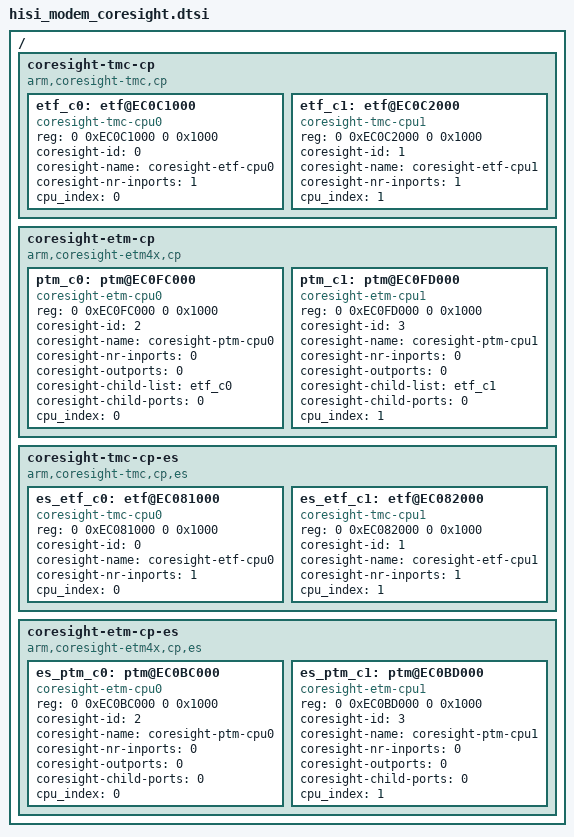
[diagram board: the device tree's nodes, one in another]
/*
 * Hisilicon Ltd Balong SOC
 */

/include/ "skeleton.dtsi"

/{
	coresight-tmc-cp {
		compatible = "arm,coresight-tmc,cp";
		ranges;
		/*tmc cpu 0*/
		etf_c0: etf@EC0C1000 {
			compatible = "coresight-tmc-cpu0";
			reg = <0 0xEC0C1000 0 0x1000>;
			
			coresight-id = <0>;
			coresight-name = "coresight-etf-cpu0";
			coresight-nr-inports = <1>;
			cpu_index = <0>;
		};
		/*tmc cpu 1*/
		etf_c1: etf@EC0C2000 {
			compatible = "coresight-tmc-cpu1";
			reg = <0 0xEC0C2000 0 0x1000>;
			
			coresight-id = <1>;
			coresight-name = "coresight-etf-cpu1";
			coresight-nr-inports = <1>;
			cpu_index = <1>;
		};		
	};
	coresight-etm-cp {
		compatible = "arm,coresight-etm4x,cp";
		ranges;
		/*etm cpu0*/
		ptm_c0: ptm@EC0FC000 {
			compatible = "coresight-etm-cpu0";
			reg = <0 0xEC0FC000 0 0x1000>;
			
			coresight-id = <2>;
			coresight-name = "coresight-ptm-cpu0";
			coresight-nr-inports = <0>;
			coresight-outports = <0>;
			coresight-child-list = <&etf_c0>;
			coresight-child-ports = <0>;
			cpu_index = <0>;
		};
		/*etm cpu1*/
		ptm_c1: ptm@EC0FD000 {
			compatible = "coresight-etm-cpu1";
			reg = <0 0xEC0FD000 0 0x1000>;
			
			coresight-id = <3>;
			coresight-name = "coresight-ptm-cpu1";
			coresight-nr-inports = <0>;
			coresight-outports = <0>;
			coresight-child-list = <&etf_c1>;
			coresight-child-ports = <0>;
			cpu_index = <1>;
		};		
	};
	coresight-tmc-cp-es {
		compatible = "arm,coresight-tmc,cp,es";
		ranges;
		/*tmc cpu 0*/
		es_etf_c0: etf@EC081000 {
			compatible = "coresight-tmc-cpu0";
			reg = <0 0xEC081000 0 0x1000>;
			
			coresight-id = <0>;
			coresight-name = "coresight-etf-cpu0";
			coresight-nr-inports = <1>;
			cpu_index = <0>;
		};
		/*tmc cpu 1*/
		es_etf_c1: etf@EC082000 {
			compatible = "coresight-tmc-cpu1";
			reg = <0 0xEC082000 0 0x1000>;
			
			coresight-id = <1>;
			coresight-name = "coresight-etf-cpu1";
			coresight-nr-inports = <1>;
			cpu_index = <1>;
		};		
	};
	coresight-etm-cp-es {
		compatible = "arm,coresight-etm4x,cp,es";
		ranges;
		/*etm cpu0*/
		es_ptm_c0: ptm@EC0BC000 {
			compatible = "coresight-etm-cpu0";
			reg = <0 0xEC0BC000 0 0x1000>;
			
			coresight-id = <2>;
			coresight-name = "coresight-ptm-cpu0";
			coresight-nr-inports = <0>;
			coresight-outports = <0>;
			coresight-child-ports = <0>;
			cpu_index = <0>;
		};
		/*etm cpu1*/
		es_ptm_c1: ptm@EC0BD000 {
			compatible = "coresight-etm-cpu1";
			reg = <0 0xEC0BD000 0 0x1000>;
			
			coresight-id = <3>;
			coresight-name = "coresight-ptm-cpu1";
			coresight-nr-inports = <0>;
			coresight-outports = <0>;
			coresight-child-ports = <0>;
			cpu_index = <1>;
		};		
	};

};
